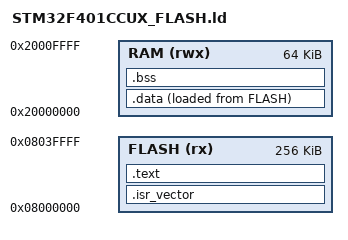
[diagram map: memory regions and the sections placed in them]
ENTRY(Reset_Handler)

MEMORY
{
    FLASH (rx)  : ORIGIN = 0x08000000, LENGTH = 256K
    RAM   (rwx) : ORIGIN = 0x20000000, LENGTH = 64K
}

SECTIONS
{
    .isr_vector : {
        KEEP(*(.isr_vector))
    } > FLASH

    .text : {
        *(.text)
        *(.text.*)
        *(.rodata)
        *(.rodata.*)
    } > FLASH

    .data : {
        _sdata = .;
        *(.data)
        *(.data.*)
        _edata = .;
    } > RAM AT > FLASH

    .bss : {
        _sbss = .;
        *(.bss)
        *(.bss.*)
        *(COMMON)
        _ebss = .;
    } > RAM

    _estack = ORIGIN(RAM) + LENGTH(RAM);
}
